# LPC178x7x register map
File version: 0.9-mod
CPU: CM3 r0p0, little endian, no MPU, no FPU, 3 interrupt priority bits
Registers are 32-bit, read-write, reset 0x0 unless marked. A register's access mark holds for its fields unless they carry their own. Offsets are from the block's base; [hi:lo] are bit positions; {n}, {i} and the like mark numbered series.

## ADC — Analog-to-Digital Converter (ADC)
Base 0x40034000
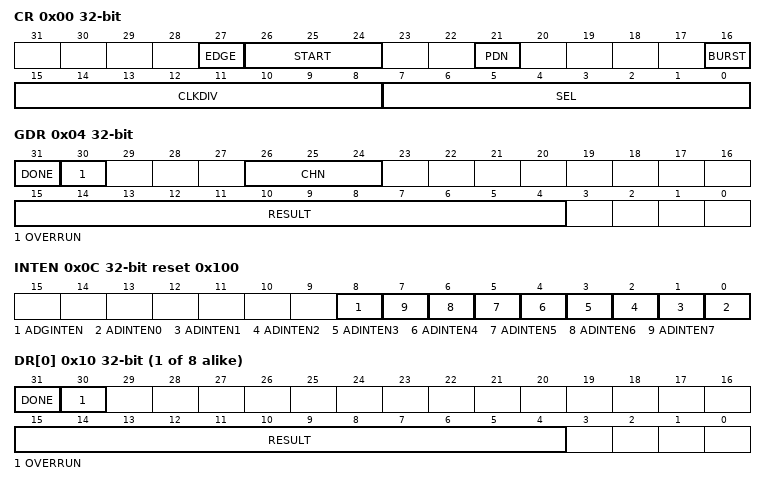
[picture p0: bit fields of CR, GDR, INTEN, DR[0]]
0x00 CR reset not defined — A/D Control Register. The ADCR register must be written to select the operating mode before A/D conversion can occur.
  [27] EDGE — This bit is significant only when the START field contains 010-111. In these cases:
    1=FALLLING (Start conversion on a falling edge on the selected CAP/MAT signal.); 0=RISING (Start conversion on a rising edge on the selected CAP/MAT signal.)
  [26:24] START — When the BURST bit is 0, these bits control whether and when an A/D conversion is started:
    0=NO_START (No start (this value should be used when clearing PDN to 0).); 1=START_NOW (Start conversion now.); 2=P2_10 (Start conversion when the edge selected by bit 27 occurs on the P2[10] pin.); 3=P1_27 (Start conversion when the edge selected by bit 27 occurs on the P1[27] pin.); 4=MAT0_1 (Start conversion when the edge selected by bit 27 occurs on MAT0.1. Note that this does not require that the MAT0.1 function appear on a device pin.); 5=MAT0_3 (Start conversion when the edge selected by bit 27 occurs on MAT0.3. Note that it is not possible to cause the MAT0.3 function to appear on a device pin.); 6=MAT1_0 (Start conversion when the edge selected by bit 27 occurs on MAT1.0. Note that this does not require that the MAT1.0 function appear on a device pin.); 7=MAT1_1 (Start conversion when the edge selected by bit 27 occurs on MAT1.1. Note that this does not require that the MAT1.1 function appear on a device pin.)
  [21] PDN — Power down mode
    1=POWERED (The A/D converter is operational.); 0=POWERDOWN (The A/D converter is in power-down mode.)
  [16] BURST — Burst mode
    1=BURST (The AD converter does repeated conversions at up to 400 kHz, scanning (if necessary) through the pins selected by bits set to ones in the SEL field. The first conversion after the start corresponds to the least-significant 1 in the SEL field, then higher numbered 1-bits (pins) if applicable. Repeated conversions can be terminated by clearing this bit, but the conversion that's in progress when this bit is cleared will be completed. START bits must be 000 when BURST = 1 or conversions will not start.); 0=SW (Conversions are software controlled and require 31 clocks.)
  [15:8] CLKDIV — The APB clock (PCLK) is divided by (this value plus one) to produce the clock for the A/D converter, which should be less than or equal to 12.4 MHz. Typically, software should program the smallest value in this field that yields a clock of 12.4 MHz or slightly less, but in certain cases (such as a high-impedance analog source) a slower clock may be desirable.
  [7:0] SEL — Selects which of the AD0[7:0] pins is (are) to be sampled and converted. For AD0, bit 0 selects Pin AD0[0], and bit 7 selects pin AD0[7]. In software-controlled mode, only one of these bits should be 1. In hardware scan mode, any value containing 1 to 8 ones is allowed. All zeroes is equivalent to 0x01.
0x04 GDR reset not defined — A/D Global Data Register. This register contains the ADC's DONE bit and the result of the most recent A/D conversion.
  [31] DONE — This bit is set to 1 when an A/D conversion completes. It is cleared when this register is read and when the ADCR is written. If the ADCR is written while a conversion is still in progress, this bit is set and a new conversion is started.
  [30] OVERRUN — This bit is 1 in burst mode if the results of one or more conversions was (were) lost and overwritten before the conversion that produced the result in the RESULT bits. This bit is cleared by reading this register.
  [26:24] CHN — These bits contain the channel from which the RESULT bits were converted (e.g. 000 identifies channel 0, 001 channel 1...).
  [15:4] RESULT — When DONE is 1, this field contains a binary fraction representing the voltage on the AD0[n] pin selected by the SEL field, as it falls within the range of VREFP to VSS. Zero in the field indicates that the voltage on the input pin was less than, equal to, or close to that on VSS, while 0xFFF indicates that the voltage on the input was close to, equal to, or greater than that on VREFP.
0x0C INTEN reset 0x100 — A/D Interrupt Enable Register. This register contains enable bits that allow the DONE flag of each A/D channel to be included or excluded from contributing to the generation of an A/D interrupt.
  [8] ADGINTEN — Interrupt enable
    0=CHANNELS (Only the individual ADC channels enabled by ADINTEN7:0 will generate interrupts.); 1=GLOBAL (The global DONE flag in ADDR is enabled to generate an interrupt in addition to any individual ADC channels that are enabled to generate interrupts.)
  [n] ADINTEN{n} (n=0..7) — Interrupt enable
    0=DISABLE (Completion of a conversion on ADC channel {n} will not generate an interrupt.); 1=ENABLE (Completion of a conversion on ADC channel {n} will generate an interrupt.)
{0x10+4i} DR[{i}] (i=0..7) ro reset not defined — A/D Channel 0 Data Register. This register contains the result of the most recent conversion completed on channel 0.
  [31] DONE — This bit is set to 1 when an A/D conversion completes. It is cleared when this register is read.
  [30] OVERRUN — This bit is 1 in burst mode if the results of one or more conversions was (were) lost and overwritten before the conversion that produced the result in the RESULT bits.This bit is cleared by reading this register.
  [15:4] RESULT — When DONE is 1, this field contains a binary fraction representing the voltage on the AD0[n] pin, as it falls within the range of VREFP to V SS. Zero in the field indicates that the voltage on the input pin was less than, equal to, or close to that on VSS, while 0xFFF indicates that the voltage on the input was close to, equal to, or greater than that on VREFP.
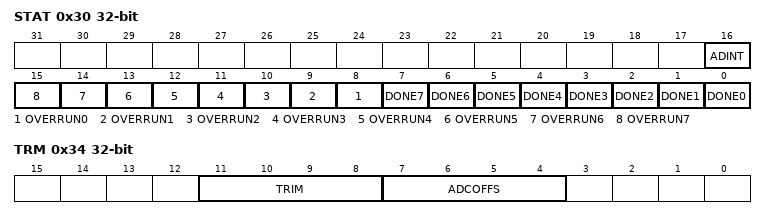
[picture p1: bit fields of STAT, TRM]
0x30 STAT ro — A/D Status Register. This register contains DONE and OVERRUN flags for all of the A/D channels, as well as the A/D interrupt/DMA flag.
  [16] ADINT — This bit is the A/D interrupt flag. It is one when any of the individual A/D channel Done flags is asserted and enabled to contribute to the A/D interrupt via the ADINTEN register.
  [n+8] OVERRUN{n} (n=0..7) — This bit mirrors the OVERRRUN status flag from the result register for A/D channel {n}.
  [n] DONE{n} (n=0..7) — This bit mirrors the DONE status flag from the result register for A/D channel {n}.
0x34 TRM — ADC trim register.
  [11:8] TRIM — written-to by boot code. Can not be overwritten by the user. These bits are locked after boot code write.
  [7:4] ADCOFFS — Offset trim bits for ADC operation. Initialized by the boot code. Can be overwritten by the user.
